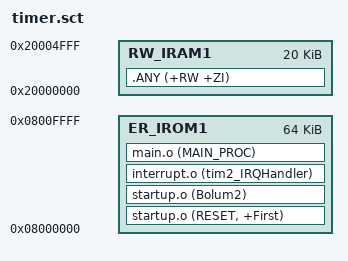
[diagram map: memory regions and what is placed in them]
; *************************************************************
; *** Scatter-Loading Description File generated by uVision ***
; *************************************************************

LR_IROM1 0x08000000 0x00010000  {    ; load region size_region
  ER_IROM1 0x08000000 0x00010000  {  ; load address = execution address
   startup.o (RESET, +First)
   startup.o (Bolum2)
   interrupt.o (tim2_IRQHandler)
   main.o (MAIN_PROC)
  }
  RW_IRAM1 0x20000000 0x00005000  {  ; RW data
   .ANY (+RW +ZI)
  }
}

